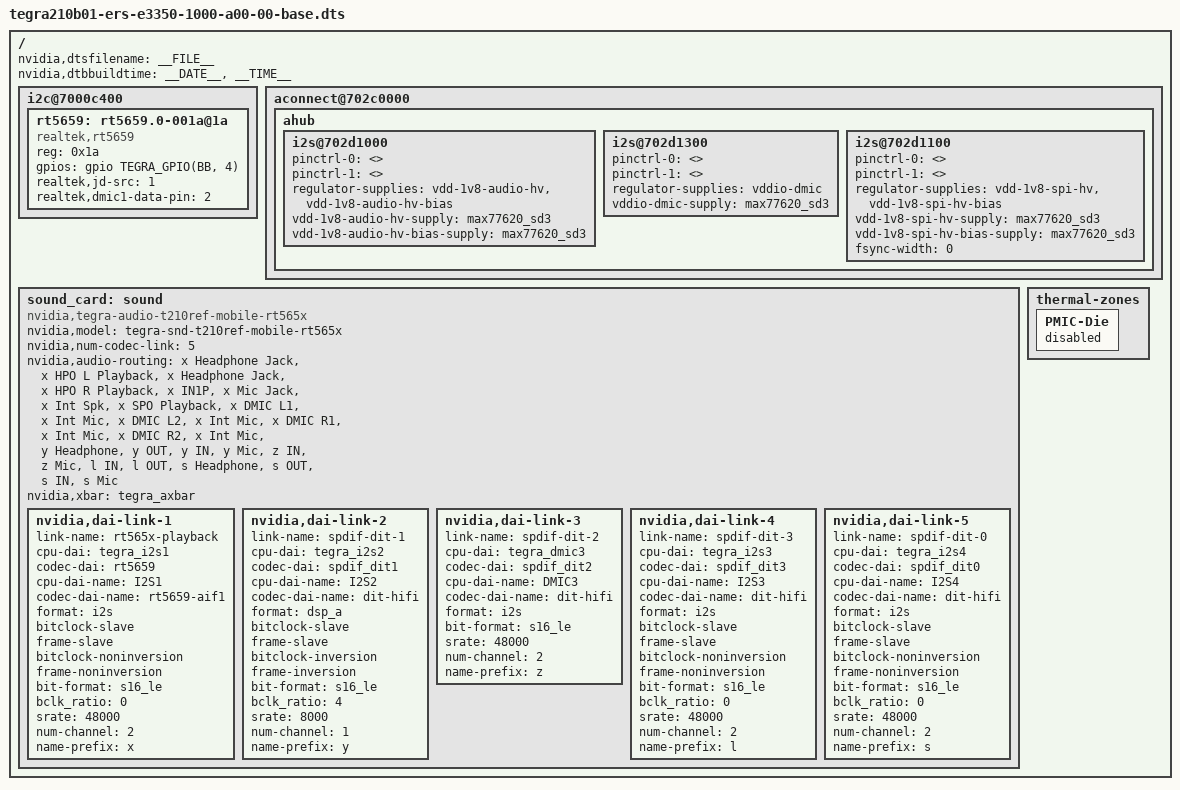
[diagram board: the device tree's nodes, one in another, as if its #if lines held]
/*
 * Copyright (c) 2017, NVIDIA CORPORATION.  All rights reserved.
 *
 * This program is free software; you can redistribute it and/or modify
 * it under the terms of the GNU General Public License as published by
 * the Free Software Foundation; version 2 of the License.
 *
 * This program is distributed in the hope that it will be useful, but WITHOUT
 * ANY WARRANTY; without even the implied warranty of MERCHANTABILITY or
 * FITNESS FOR A PARTICULAR PURPOSE.  See the GNU General Public License for
 * more details.
 *
 * You should have received a copy of the GNU General Public License along
 * with this program; if not, write to the Free Software Foundation, Inc.,
 * 51 Franklin Street, Fifth Floor, Boston, MA  02110-1301, USA.
 */

#include "ers-platforms/tegra210b01-ers-e3350-1000-a00-00-common.dtsi"
#include "ers-platforms/tegra210b01-cvb-e3320-1000-a00.dtsi"
#include "ers-platforms/tegra210b01-ers-power-tree-e2175-1122-a00.dtsi"
#include "ers-platforms/tegra210b01-e3350-1000-a00-padvoltage-default.dtsi"
#include "ers-platforms/tegra210b01-e3350-1000-a00-pinmux.dtsi"
#include "ers-plugin-manager/tegra210b01-ers-plugin-manager.dtsi"

/ {
	nvidia,dtsfilename = __FILE__;
	nvidia,dtbbuildtime = __DATE__, __TIME__;

	i2c@7000c400 {
		rt5659: rt5659.0-001a@1a {
			compatible = "realtek,rt5659";
			reg = <0x1a>;
			gpios = <&gpio TEGRA_GPIO(BB, 4) GPIO_ACTIVE_HIGH>;

			/* refer include/sound/rt5659.h for the values to be used */
			realtek,jd-src = <1>; /* RT5659_JD3 */
			realtek,dmic1-data-pin = <2>; /* RT5659_DMIC1_DATA_GPIO5 */
		};
	};

#if defined(LINUX_VERSION) && LINUX_VERSION >= 409
	aconnect@702c0000 {
#endif
	ahub {
		i2s@702d1000 {
			pinctrl-names = "dap_active", "dap_inactive";
			pinctrl-0 = <>;
			pinctrl-1 = <>;
			regulator-supplies = "vdd-1v8-audio-hv", "vdd-1v8-audio-hv-bias";
			vdd-1v8-audio-hv-supply = <&max77620_sd3>;
			vdd-1v8-audio-hv-bias-supply = <&max77620_sd3>;
		};

		i2s@702d1300 {
			pinctrl-names = "dap_active", "dap_inactive";
			pinctrl-0 = <>;
			pinctrl-1 = <>;
			regulator-supplies = "vddio-dmic";
			vddio-dmic-supply = <&max77620_sd3>;
		};

		i2s@702d1100 {
			pinctrl-names = "dap_active", "dap_inactive";
			pinctrl-0 = <>;
			pinctrl-1 = <>;
			regulator-supplies = "vdd-1v8-spi-hv", "vdd-1v8-spi-hv-bias";
			vdd-1v8-spi-hv-supply = <&max77620_sd3>;
			vdd-1v8-spi-hv-bias-supply = <&max77620_sd3>;
			fsync-width = <0>;
		};
	};
#if defined(LINUX_VERSION) && LINUX_VERSION >= 409
	};
#endif

	sound_card: sound {
		compatible = "nvidia,tegra-audio-t210ref-mobile-rt565x";
		nvidia,model = "tegra-snd-t210ref-mobile-rt565x";

		nvidia,num-codec-link = <5>;

		nvidia,audio-routing =
						"x Headphone Jack",	"x HPO L Playback",
						"x Headphone Jack",	"x HPO R Playback",
						"x IN1P",		"x Mic Jack",
						"x Int Spk",		"x SPO Playback",
						"x DMIC L1",		"x Int Mic",
						"x DMIC L2",		"x Int Mic",
						"x DMIC R1",		"x Int Mic",
						"x DMIC R2",		"x Int Mic",
						"y Headphone",		"y OUT",
						"y IN",			"y Mic",
						"z IN",			"z Mic",
						"l IN",			"l OUT",
						"s Headphone",		"s OUT",
						"s IN",			"s Mic";

		nvidia,xbar = <&tegra_axbar>;

		/* The codec-dai here is initialized to dummy and will be   */
		/* replaced with rt565x codec-dai on detecting super-module */
		nvidia,dai-link-1 {
			link-name = "rt565x-playback";
			cpu-dai = <&tegra_i2s1>;
			codec-dai = <&rt5659>;
			cpu-dai-name = "I2S1";
			codec-dai-name = "rt5659-aif1";
			format = "i2s";
			bitclock-slave;
			frame-slave;
			bitclock-noninversion;
			frame-noninversion;
			bit-format = "s16_le";
			bclk_ratio = <0>;
			srate = <48000>;
			num-channel = <2>;
			name-prefix = "x";
		};

		nvidia,dai-link-2 {
			link-name = "spdif-dit-1";
			cpu-dai = <&tegra_i2s2>;
			codec-dai = <&spdif_dit1>;
			cpu-dai-name = "I2S2";
			codec-dai-name = "dit-hifi";
			format = "dsp_a";
			bitclock-slave;
			frame-slave;
			bitclock-inversion;
			frame-inversion;
			bit-format = "s16_le";
			bclk_ratio = <4>;
			srate = <8000>;
			num-channel = <1>;
			name-prefix = "y";
		};

		nvidia,dai-link-3 {
			link-name = "spdif-dit-2";
			cpu-dai = <&tegra_dmic3>;
			codec-dai = <&spdif_dit2>;
			cpu-dai-name = "DMIC3";
			codec-dai-name = "dit-hifi";
			format = "i2s";
			bit-format = "s16_le";
			srate = <48000>;
			num-channel = <2>;
			name-prefix = "z";
		};

		nvidia,dai-link-4 {
			link-name = "spdif-dit-3";
			cpu-dai = <&tegra_i2s3>;
			codec-dai = <&spdif_dit3>;
			cpu-dai-name = "I2S3";
			codec-dai-name = "dit-hifi";
			format = "i2s";
			bitclock-slave;
			frame-slave;
			bitclock-noninversion;
			frame-noninversion;
			bit-format = "s16_le";
			bclk_ratio = <0>;
			srate = <48000>;
			num-channel = <2>;
			name-prefix = "l";
		};

		nvidia,dai-link-5 {
			link-name = "spdif-dit-0";
			cpu-dai = <&tegra_i2s4>;
			codec-dai = <&spdif_dit0>;
			cpu-dai-name = "I2S4";
			codec-dai-name = "dit-hifi";
			format = "i2s";
			bitclock-slave;
			frame-slave;
			bitclock-noninversion;
			frame-noninversion;
			bit-format = "s16_le";
			bclk_ratio = <0>;
			srate = <48000>;
			num-channel = <2>;
			name-prefix = "s";
		};
	};

	thermal-zones {
		PMIC-Die {
			status = "disabled";
		};
	};
};
